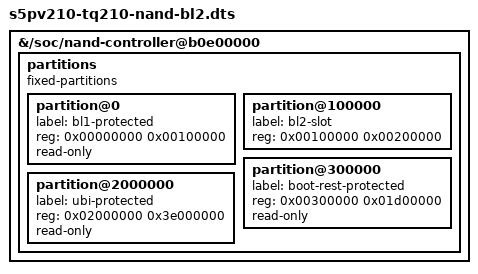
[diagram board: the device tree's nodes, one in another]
// SPDX-License-Identifier: GPL-2.0
#include "s5pv210-tq210-nand-bch.dts"

/* Only the fixed BL2 slot is writable. No UBI attachment. */
&{/soc/nand-controller@b0e00000} {
	partitions {
		compatible = "fixed-partitions";
		#address-cells = <1>;
		#size-cells = <1>;
		partition@0 {
			label = "bl1-protected";
			reg = <0x00000000 0x00100000>;
			read-only;
		};
		partition@100000 {
			label = "bl2-slot";
			reg = <0x00100000 0x00200000>;
		};
		partition@300000 {
			label = "boot-rest-protected";
			reg = <0x00300000 0x01d00000>;
			read-only;
		};
		partition@2000000 {
			label = "ubi-protected";
			reg = <0x02000000 0x3e000000>;
			read-only;
		};
	};
};
